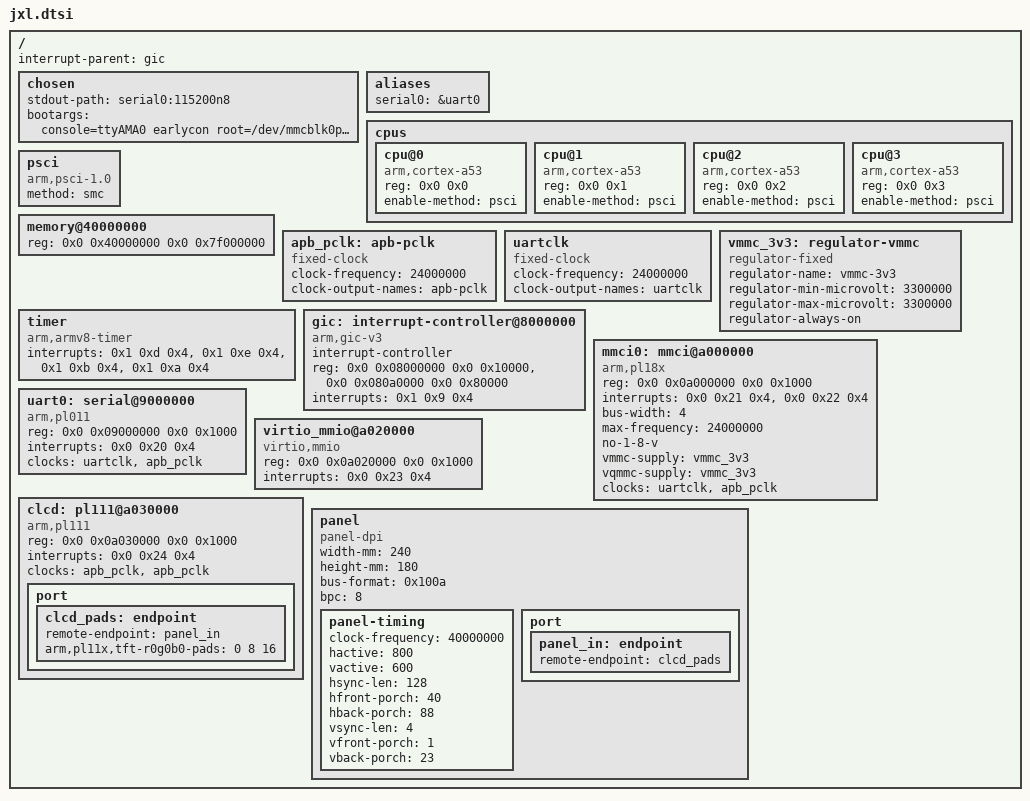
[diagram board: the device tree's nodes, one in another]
/ {
	#address-cells = <2>;
	#size-cells = <2>;
	interrupt-parent = <&gic>;

	chosen {
		stdout-path = "serial0:115200n8";
		bootargs = "console=ttyAMA0 earlycon root=/dev/mmcblk0p1 rootfstype=ext4 rw init=/init";
	};

	aliases {
		serial0 = &uart0;
	};

	cpus {
		#address-cells = <2>;
		#size-cells = <0>;

		cpu@0 {
			device_type = "cpu";
			compatible = "arm,cortex-a53";
			reg = <0x0 0x0>;
			enable-method = "psci";
		};

		cpu@1 {
			device_type = "cpu";
			compatible = "arm,cortex-a53";
			reg = <0x0 0x1>;
			enable-method = "psci";
		};

		cpu@2 {
			device_type = "cpu";
			compatible = "arm,cortex-a53";
			reg = <0x0 0x2>;
			enable-method = "psci";
		};

		cpu@3 {
			device_type = "cpu";
			compatible = "arm,cortex-a53";
			reg = <0x0 0x3>;
			enable-method = "psci";
		};
	};

	psci {
		compatible = "arm,psci-1.0", "arm,psci-0.2";
		method = "smc";
	};

	memory@40000000 {
		device_type = "memory";
		reg = <0x0 0x40000000 0x0 0x7f000000>;
	};

	apb_pclk: apb-pclk {
		compatible = "fixed-clock";
		#clock-cells = <0>;
		clock-frequency = <24000000>;
		clock-output-names = "apb-pclk";
	};

	uartclk: uartclk {
		compatible = "fixed-clock";
		#clock-cells = <0>;
		clock-frequency = <24000000>;
		clock-output-names = "uartclk";
	};

	vmmc_3v3: regulator-vmmc {
		compatible = "regulator-fixed";
		regulator-name = "vmmc-3v3";
		regulator-min-microvolt = <3300000>;
		regulator-max-microvolt = <3300000>;
		regulator-always-on;
	};

	timer {
		compatible = "arm,armv8-timer";
		interrupts = <0x1 0xd 0x4>,
			     <0x1 0xe 0x4>,
			     <0x1 0xb 0x4>,
			     <0x1 0xa 0x4>;
	};

	gic: interrupt-controller@8000000 {
		compatible = "arm,gic-v3";
		#address-cells = <2>;
		#interrupt-cells = <3>;
		#size-cells = <2>;
		interrupt-controller;
		reg = <0x0 0x08000000 0x0 0x10000>,
		      <0x0 0x080a0000 0x0 0x80000>;
		interrupts = <0x1 0x9 0x4>;
	};

	mmci0: mmci@a000000 {
		compatible = "arm,pl18x", "arm,primecell";
		reg = <0x0 0x0a000000 0x0 0x1000>;
		interrupts = <0x0 0x21 0x4>, <0x0 0x22 0x4>;
		bus-width = <4>;
		max-frequency = <24000000>;
		no-1-8-v;
		vmmc-supply = <&vmmc_3v3>;
		vqmmc-supply = <&vmmc_3v3>;
		clocks = <&uartclk>, <&apb_pclk>;
		clock-names = "mclk", "apb_pclk";
		status = "okay";
	};

	uart0: serial@9000000 {
		compatible = "arm,pl011", "arm,primecell";
		reg = <0x0 0x09000000 0x0 0x1000>;
		interrupts = <0x0 0x20 0x4>;
		clocks = <&uartclk>, <&apb_pclk>;
		clock-names = "uartclk", "apb_pclk";
		status = "okay";
	};

	virtio_mmio@a020000 {
		compatible = "virtio,mmio";
		reg = <0x0 0x0a020000 0x0 0x1000>;
		/*
		 * Matches JXL_SOC_IRQ_VIRTIO_MMIO in qemu/hw/arm/jxl/jxl_soc.h
		 * (gpio_in[35] = SPI 35 = GIC INT 67); kept consistent with the
		 * UART/MMCI cells that already encode the qemu enum value.
		 */
		interrupts = <0x0 0x23 0x4>;
	};

	clcd: pl111@a030000 {
		compatible = "arm,pl111", "arm,primecell";
		reg = <0x0 0x0a030000 0x0 0x1000>;
		/* JXL_SOC_IRQ_CLCD = 36 (SPI 36, GIC INT 68). */
		interrupts = <0x0 0x24 0x4>;
		clocks = <&apb_pclk>, <&apb_pclk>;
		clock-names = "clcdclk", "apb_pclk";

		port {
			clcd_pads: endpoint {
				remote-endpoint = <&panel_in>;
				/*
				 * Standard ARM CLCD TFT pin order: RGB lanes
				 * starting at bits 0/8/16 of the pixel word.
				 */
				arm,pl11x,tft-r0g0b0-pads = <0 8 16>;
			};
		};
	};

	panel {
		/*
		 * Faux DPI panel driven by PL111. QEMU's pl111 model just renders
		 * whatever the framebuffer registers describe, so the timings
		 * below only need to be self-consistent SVGA values; pick stock
		 * 800x600@60.
		 */
		compatible = "panel-dpi";

		width-mm = <240>;
		height-mm = <180>;

		bus-format = <0x100a>;  /* MEDIA_BUS_FMT_RGB888_1X24 */
		bpc = <8>;

		panel-timing {
			clock-frequency = <40000000>;
			hactive = <800>;
			vactive = <600>;
			hsync-len = <128>;
			hfront-porch = <40>;
			hback-porch = <88>;
			vsync-len = <4>;
			vfront-porch = <1>;
			vback-porch = <23>;
		};

		port {
			panel_in: endpoint {
				remote-endpoint = <&clcd_pads>;
			};
		};
	};
};
